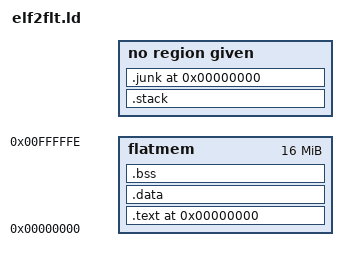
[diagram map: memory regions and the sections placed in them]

ENTRY (__start)

MEMORY {
	flatmem : ORIGIN = 0x0, LENGTH = 0xffffff
}

SECTIONS {
	.text 0x0 : {
		. = . + 4;
		. = ALIGN(0x4) ;
		_stext = . ;
		*(.text)
		*(.text.*)
		*(.gnu.warning)
		*(.stub)
		*(.gnu.linkonce.t*)
		*(.glue_7t)
		*(.glue_7)
		*(.jcr)
		*(.init)
		*(.fini)

W_RODAT		*(.rodata)
W_RODAT		*(.rodata1)
W_RODAT		*(.rodata.*)

		/* This is special code area at the end of the normal
		   text section.  It contains a small lookup table at
		   the start followed by the code pointed to by entries
		   in the lookup table.  */
		. = ALIGN (4) ;
		PROVIDE(__ctbp = .);
		*(.call_table_data)
		*(.call_table_text)

		. = ALIGN(0x20) ;
		_etext = . ;
	} > flatmem
	.data : {
		. = ALIGN(0x4) ;
		_sdata = . ;
		__data_start = . ;
		data_start = . ;
		*(.got.plt)
		*(.got)
		FILL(0) ;
		. = ALIGN(0x20) ; 
		LONG(-1)
		. = ALIGN(0x20) ; 
		*(.gnu.linkonce.r*)
		*(.data)
		*(.data1)
		*(.data.*)
		*(.gnu.linkonce.d*)
		*(.data1)
R_RODAT		*(.rodata)
R_RODAT		*(.rodata1)
R_RODAT		*(.rodata.*)
		*(.eh_frame)
		*(.gcc_except_table)
		*(.sdata) 
		*(.sdata.*)
		*(.gnu.linkonce.s.*)
		*(__libc_atexit)
		*(__libc_subinit)
		*(__libc_subfreeres)
		*(.note.ABI-tag)

		. = ALIGN(4) ;
		__CTOR_LIST__ = .;
		LONG((__CTOR_END__ - __CTOR_LIST__) / 4 - 2)
		*(.ctors)
		LONG(0)
		__CTOR_END__ = .;
		__DTOR_LIST__ = .;
		LONG((__DTOR_END__ - __DTOR_LIST__) / 4 - 2)
		*(.dtors)
		LONG(0)
		__DTOR_END__ = .;

		. = ALIGN(0x10) ; 
		_edata = . ;
	} > flatmem
	.bss : {
		. = ALIGN(0x4) ;
		_sbss = ALIGN(0x4) ;
		__bss_start = . ;
		*(.dynsbss)
		*(.sbss)
		*(.sbss.*)
		*(.scommon)
		*(.dynbss)
		*(.bss)
		*(.bss.*)
		*(.bss*)
		*(.gnu.linkonce.b*)
		*(COMMON)
		. = ALIGN(0x10) ;
		_ebss = . ;
		_end = . ;
		end = . ;
	} > flatmem
	.stack : {
		. = ALIGN(0x4);
		__stack_start = .;
	}
	.junk 0 : { *(.rel*) *(.rela*) }
	/* Stabs debugging sections.    */
	.stab 0 : { *(.stab) }
	.stabstr 0 : { *(.stabstr) }
	.stab.excl 0 : { *(.stab.excl) }
	.stab.exclstr 0 : { *(.stab.exclstr) }
	.stab.index 0 : { *(.stab.index) }
	.stab.indexstr 0 : { *(.stab.indexstr) }
	.comment 0 : { *(.comment) }
  /* DWARF debug sections.
     Symbols in the DWARF debugging sections are relative to the beginning
     of the section so we begin them at 0.  */
  /* DWARF 1 */
  .debug          0 : { *(.debug) }
  .line           0 : { *(.line) }
  /* GNU DWARF 1 extensions */
  .debug_srcinfo  0 : { *(.debug_srcinfo) }
  .debug_sfnames  0 : { *(.debug_sfnames) }
  /* DWARF 1.1 and DWARF 2 */
  .debug_aranges  0 : { *(.debug_aranges) }
  .debug_pubnames 0 : { *(.debug_pubnames) }
  /* DWARF 2 */
  .debug_info     0 : { *(.debug_info .gnu.linkonce.wi.*) }
  .debug_abbrev   0 : { *(.debug_abbrev) }
  .debug_line     0 : { *(.debug_line) }
  .debug_frame    0 : { *(.debug_frame) }
  .debug_str      0 : { *(.debug_str) }
  .debug_loc      0 : { *(.debug_loc) }
  .debug_macinfo  0 : { *(.debug_macinfo) }
  /* SGI/MIPS DWARF 2 extensions */
  .debug_weaknames 0 : { *(.debug_weaknames) }
  .debug_funcnames 0 : { *(.debug_funcnames) }
  .debug_typenames 0 : { *(.debug_typenames) }
  .debug_varnames  0 : { *(.debug_varnames) }
}
